VERSION ""

NS_ :

BS_:

BU_: BMS ZF ABS VCU

BO_ 2364576807 BMS_MSG02: 8 BMS
 SG_ DCL_Max_Current_Charge : 16|16@1+ (0.05,-1600) [-1600|1612.8] "A" Vector__XXX
 SG_ DCL_Max_Current_DisCharge : 0|16@1+ (0.05,-1600) [-1600|1612.8] "A" Vector__XXX

BO_ 2566832475 VDHR: 8 VCU
 SG_ HghRslutionTotalVehicleDistance : 0|32@1+ (0.005,0) [0|21055400] "km" Vector__XXX

BO_ 2364575953 BMS_MSG01: 8 BMS
 SG_ DCL_Current : 48|16@1+ (0.05,-16000) [-16000|16000] "A" Vector__XXX
 SG_ DCL_Volt : 32|16@1+ (0.05,0) [0|3212] "v" Vector__XXX

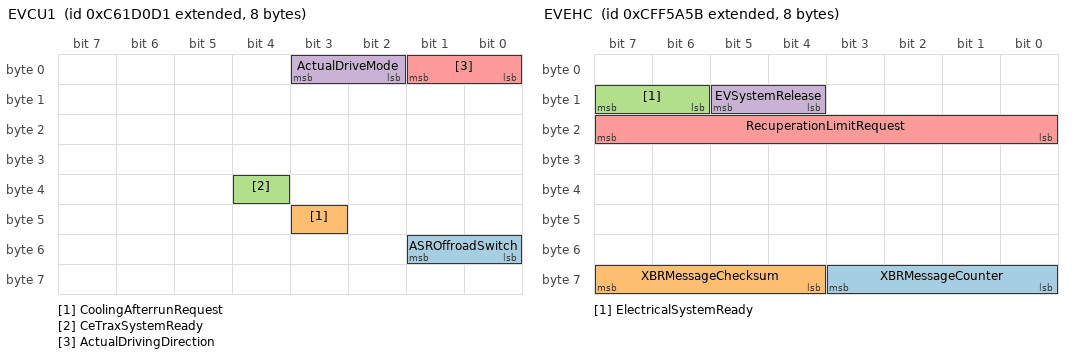
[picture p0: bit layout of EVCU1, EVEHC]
BO_ 2355220689 EVCU1: 8 Vector__XXX
 SG_ ASROffroadSwitch : 48|2@1+ (1,0) [0|3] "" Vector__XXX
 SG_ CoolingAfterrunRequest : 43|1@1+ (1,0) [0|1] "" Vector__XXX
 SG_ CeTraxSystemReady : 36|1@1+ (1,0) [0|0] "" Vector__XXX
 SG_ ActualDriveMode : 2|2@1+ (1,0) [0|0] "" Vector__XXX
 SG_ ActualDrivingDirection : 0|2@1+ (1,0) [0|0] "" Vector__XXX

BO_ 2348876635 TC1_Ext: 8 Vector__XXX
 SG_ Disengage_Driveline_Request : 0|2@1+ (1,0) [0|3] "" Vector__XXX

BO_ 2566871643 BMS_MSG06: 8 VCU
 SG_ DCL_Min_Voltage : 16|16@1+ (0.05,0) [0|3212.75] "" Vector__XXX
 SG_ DCL_Max_Voltage : 0|16@1+ (0.05,0) [0|3212.75] "" Vector__XXX

BO_ 2566698791 BMS_MSG03: 8 BMS
 SG_ State_Of_Charge : 0|16@1+ (0.0025,0) [0|160.6375] "%" Vector__XXX

BO_ 2365545051 EVEHC: 8 VCU
 SG_ XBRMessageCounter : 56|4@1+ (1,0) [0|15] "" Vector__XXX
 SG_ XBRMessageChecksum : 60|4@1+ (1,0) [0|15] "" Vector__XXX
 SG_ ElectricalSystemReady : 14|2@1+ (1,0) [0|3] "" Vector__XXX
 SG_ EVSystemRelease : 12|2@1+ (1,0) [0|3] "" Vector__XXX
 SG_ RecuperationLimitRequest : 16|8@1+ (0.4,0) [0|100] "%" Vector__XXX

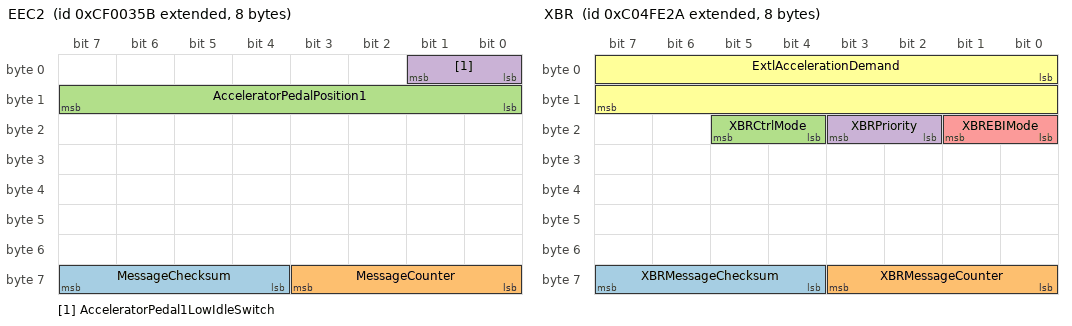
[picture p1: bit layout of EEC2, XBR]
BO_ 2364539739 EEC2: 8 VCU
 SG_ MessageChecksum : 60|4@1+ (1,0) [0|15] "" Vector__XXX
 SG_ MessageCounter : 56|4@1+ (1,0) [0|15] "" Vector__XXX
 SG_ AcceleratorPedalPosition1 : 8|8@1+ (0.4,0) [0|100] "%" Vector__XXX
 SG_ AcceleratorPedal1LowIdleSwitch : 0|2@1+ (1,0) [0|3] "" Vector__XXX

BO_ 2566845787 AMB: 8 VCU
 SG_ AMB1 : 16|16@1+ (0.03125,-273) [-273|1734] "deg C" Vector__XXX

BO_ 2349137450 XBR: 8 Vector__XXX
 SG_ XBRMessageChecksum : 60|4@1+ (1,0) [0|15] "" Vector__XXX
 SG_ XBRMessageCounter : 56|4@1+ (1,0) [0|15] "" Vector__XXX
 SG_ XBRCtrlMode : 20|2@1+ (1,0) [0|3] "" Vector__XXX
 SG_ XBRPriority : 18|2@1+ (1,0) [0|3] "" Vector__XXX
 SG_ XBREBIMode : 16|2@1+ (1,0) [0|3] "" Vector__XXX
 SG_ ExtlAccelerationDemand : 0|16@1+ (0.000488281,-15.687) [-15.687|15.687] "m/s²" Vector__XXX

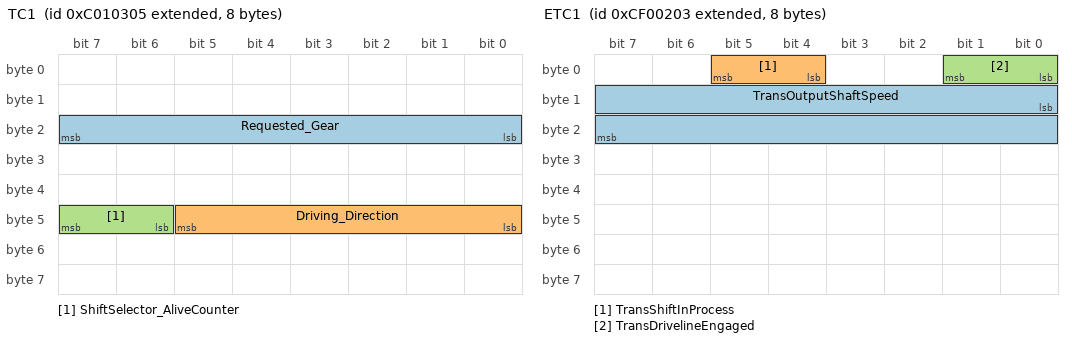
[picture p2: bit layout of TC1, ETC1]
BO_ 2348876549 TC1: 8 Vector__XXX
 SG_ Requested_Gear : 16|8@1+ (1,0) [125|252] "" Vector__XXX
 SG_ Driving_Direction : 40|6@1+ (1,0) [0|0] "" Vector__XXX
 SG_ ShiftSelector_AliveCounter : 46|2@1+ (1,0) [0|3] "" Vector__XXX

BO_ 2566840580 RC: 19 Vector__XXX
 SG_ PercentTorqueAtPeakTorquePoint5 : 144|8@1+ (1,-125) [-125|125] "%" Vector__XXX
 SG_ ReferenceRetarderTorque : 128|16@1+ (1,0) [0|64255] "Nm" Vector__XXX
 SG_ RetarderSpeedAtPeakTorquePoint5 : 112|16@1+ (0.125,0) [0|8031.88] "rpm" Vector__XXX
 SG_ PercentTorqueAtPoint4 : 104|8@1+ (1,-125) [-125|125] "%" Vector__XXX
 SG_ RetarderSpeedAtPoint4 : 88|16@1+ (0.125,0) [0|8031.88] "rpm" Vector__XXX
 SG_ PercentTorqueAtPoint3 : 80|8@1+ (1,-125) [-125|125] "%" Vector__XXX
 SG_ RetarderSpeedAtPoint3 : 64|16@1+ (0.125,0) [0|8031.88] "rpm" Vector__XXX
 SG_ PercentTorqueAtMaxSpeedPoint2 : 56|8@1+ (1,-125) [-125|125] "%" Vector__XXX
 SG_ MaxRetarderSpeedPoint2 : 40|16@1+ (0.125,0) [0|8031.88] "rpm" Vector__XXX
 SG_ PercentTorqueAtIdlePoint1 : 32|8@1+ (1,-125) [-125|125] "%" Vector__XXX
 SG_ RetarderSpeedAtIdlePoint1 : 16|16@1+ (0.125,0) [0|8031.88] "rpm" Vector__XXX
 SG_ DrivingDirection : 8|32@1+ (1,0) [0|250] "steps" Vector__XXX
 SG_ RetarderLocation : 4|4@1+ (1,0) [0|15] "" Vector__XXX
 SG_ RetarderType : 0|4@1+ (1,0) [0|15] "" Vector__XXX

BO_ 2566801923 ETC7: 8 Vector__XXX
 SG_ TransReadyForBrakeRelease : 8|2@1+ (1,0) [0|3] "" Vector__XXX

BO_ 2565866755 ETC2: 8 Vector__XXX
 SG_ TransCurrentGear : 24|8@1+ (1,-125) [-125|125] "" Vector__XXX
 SG_ TransSelectedGear : 0|8@1+ (1,-125) [-125|125] "" Vector__XXX

BO_ 2364539395 ETC1: 8 Vector__XXX
 SG_ TransOutputShaftSpeed : 8|16@1+ (0.125,0) [0|8031.88] "rpm" Vector__XXX
 SG_ TransShiftInProcess : 4|2@1+ (1,0) [0|3] "" Vector__XXX
 SG_ TransDrivelineEngaged : 0|2@1+ (1,0) [0|3] "" Vector__XXX

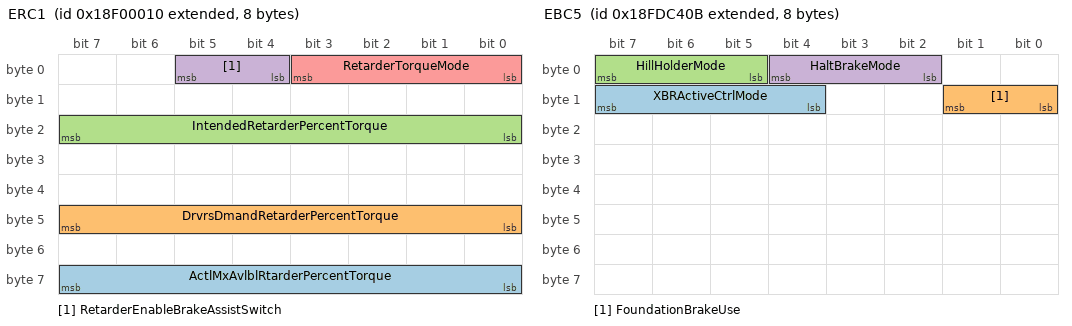
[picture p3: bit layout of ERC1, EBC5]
BO_ 2565865488 ERC1: 8 Vector__XXX
 SG_ ActlMxAvlblRtarderPercentTorque : 56|8@1+ (1,-125) [-125|125] "%" Vector__XXX
 SG_ DrvrsDmandRetarderPercentTorque : 40|8@1+ (1,-125) [-125|125] "%" Vector__XXX
 SG_ IntendedRetarderPercentTorque : 16|8@1+ (1,-125) [-125|125] "%" Vector__XXX
 SG_ RetarderEnableBrakeAssistSwitch : 4|2@1+ (1,0) [0|3] "" Vector__XXX
 SG_ RetarderTorqueMode : 0|4@1+ (1,0) [0|15] "" Vector__XXX

BO_ 2566841088 EC1: 21 Vector__XXX
 SG_ EngReferenceTorque : 152|16@1+ (1,0) [0|64255] "Nm" Vector__XXX
 SG_ EngPercentTorqueAtPoint5 : 112|8@1+ (1,-125) [-125|125] "%" Vector__XXX
 SG_ EngSpeedAtPoint5 : 96|16@1+ (0.125,0) [0|8031.88] "rpm" Vector__XXX
 SG_ EngPercentTorqueAtPoint4 : 88|8@1+ (1,-125) [-125|125] "%" Vector__XXX
 SG_ EngSpeedAtPoint4 : 72|16@1+ (0.125,0) [0|8031.88] "rpm" Vector__XXX
 SG_ EngPercentTorqueAtPoint3 : 64|8@1+ (1,-125) [-125|125] "%" Vector__XXX
 SG_ EngSpeedAtPoint3 : 48|16@1+ (0.125,0) [0|8031.88] "rpm" Vector__XXX
 SG_ EngPercentTorqueAtPoint2 : 40|8@1+ (1,-125) [-125|125] "%" Vector__XXX
 SG_ EngSpeedAtPoint2 : 24|16@1+ (0.125,0) [0|8031.88] "rpm" Vector__XXX
 SG_ EngPercentTorqueAtIdlePoint1 : 16|8@1+ (1,-125) [-125|125] "%" Vector__XXX
 SG_ EngSpeedAtIdlePoint1 : 0|16@1+ (0.125,0) [0|8031.88] "rpm" Vector__XXX

BO_ 2566767627 EBC5: 8 ABS
 SG_ XBRActiveCtrlMode : 12|4@1+ (1,0) [0|15] "" Vector__XXX
 SG_ FoundationBrakeUse : 8|2@1+ (1,0) [0|3] "" Vector__XXX
 SG_ HillHolderMode : 5|3@1+ (1,0) [0|7] "" Vector__XXX
 SG_ HaltBrakeMode : 2|3@1+ (1,0) [0|7] "" Vector__XXX

BO_ 2566831883 EBC2: 8 ABS
 SG_ FrontAxleSpeed : 0|16@1+ (0.00390625,0) [0|250.996] "km/h" Vector__XXX

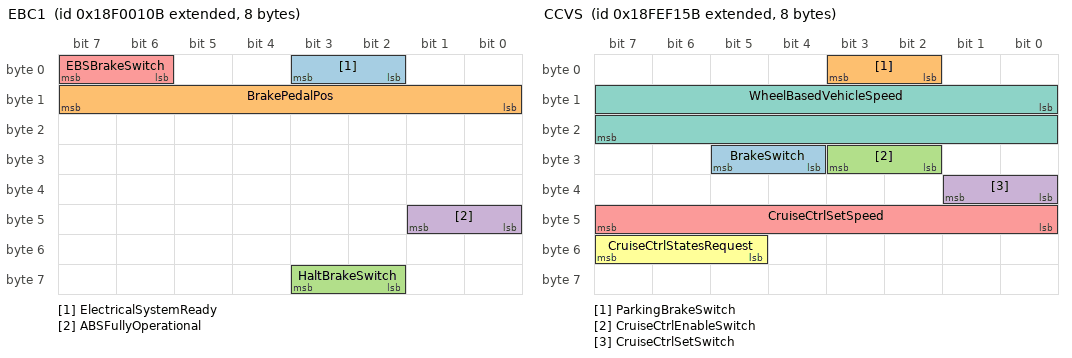
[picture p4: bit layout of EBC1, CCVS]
BO_ 2565865739 EBC1: 8 ABS
 SG_ ElectricalSystemReady : 2|2@1+ (1,0) [0|3] "" Vector__XXX
 SG_ BrakePedalPos : 8|8@1+ (0.4,0) [0|100] "%" Vector__XXX
 SG_ HaltBrakeSwitch : 58|2@1+ (1,0) [0|3] "" Vector__XXX
 SG_ ABSFullyOperational : 40|2@1+ (1,0) [0|3] "" Vector__XXX
 SG_ EBSBrakeSwitch : 6|2@1+ (1,0) [0|3] "" Vector__XXX

BO_ 2566844763 CCVS: 8 VCU
 SG_ BrakeSwitch : 28|2@1+ (1,0) [0|3] "" Vector__XXX
 SG_ ParkingBrakeSwitch : 2|2@1+ (1,0) [0|3] "" Vector__XXX
 SG_ CruiseCtrlEnableSwitch : 26|2@1+ (1,0) [0|3] "" Vector__XXX
 SG_ CruiseCtrlSetSwitch : 32|2@1+ (1,0) [0|3] "" Vector__XXX
 SG_ CruiseCtrlSetSpeed : 40|8@1+ (1,0) [0|250] "km/h" Vector__XXX
 SG_ CruiseCtrlStatesRequest : 53|3@1+ (1,0) [0|7] "sts" Vector__XXX
 SG_ WheelBasedVehicleSpeed : 8|16@1+ (0.00390625,0) [0|250] "km/h" Vector__XXX

BO_ 2566834778 DM1: 22 ZF
 SG_ FlashRedStopLamp : 12|2@1+ (1,0) [0|3] "" Vector__XXX
 SG_ FlashProtectLamp : 8|2@1+ (1,0) [0|3] "" Vector__XXX
 SG_ FlashMalfuncIndicatorLamp : 14|2@1+ (1,0) [0|3] "" Vector__XXX
 SG_ FlashAmberWarningLamp : 10|2@1+ (1,0) [0|3] "" Vector__XXX
 SG_ MalfunctionIndicatorLampStatus : 6|2@1+ (1,0) [0|3] "" Vector__XXX
 SG_ AmberWarningLampStatus : 2|2@1+ (1,0) [0|3] "" Vector__XXX
 SG_ RedStopLampState : 4|2@1+ (1,0) [0|3] "" Vector__XXX
 SG_ ProtectLampStatus : 0|2@1+ (1,0) [0|3] "" Vector__XXX
 SG_ DTC5 : 144|32@1+ (1,0) [-1|0] "" Vector__XXX
 SG_ DTC4 : 112|32@1+ (1,0) [-1|0] "" Vector__XXX
 SG_ DTC3 : 80|32@1+ (1,0) [-1|0] "" Vector__XXX
 SG_ DTC2 : 48|32@1+ (1,0) [-1|0] "" Vector__XXX
 SG_ DTC1 : 16|32@1+ (1,0) [-1|0] "" Vector__XXX

BO_ 2566846241 VEP: 8 Vector__XXX
 SG_ BATT_VOLTAGE_24V : 48|16@1+ (0.05,0) [0|3212.75] "V" Vector__XXX

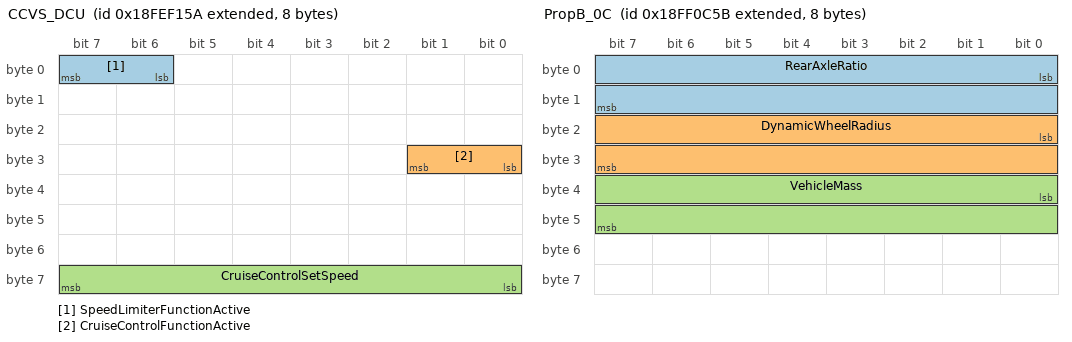
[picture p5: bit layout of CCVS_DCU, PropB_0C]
BO_ 2566844762 CCVS_DCU: 8 ZF
 SG_ SpeedLimiterFunctionActive : 6|2@1+ (1,0) [0|3] "" Vector__XXX
 SG_ CruiseControlFunctionActive : 24|2@1+ (1,0) [0|3] "" Vector__XXX
 SG_ CruiseControlSetSpeed : 56|8@1+ (1,0) [0|250] "kph" Vector__XXX

BO_ 2566851675 PropB_0C: 8 VCU
 SG_ RearAxleRatio : 0|16@1+ (0.01,0) [0|642.55] "" Vector__XXX
 SG_ DynamicWheelRadius : 16|16@1+ (0.1,0) [0|6425.5] "mm" Vector__XXX
 SG_ VehicleMass : 32|16@1+ (2,0) [0|128510] "kg" Vector__XXX

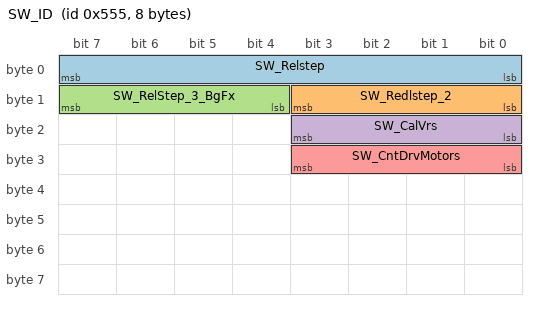
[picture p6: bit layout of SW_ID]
BO_ 1365 SW_ID: 8 ZF
 SG_ SW_Relstep : 0|8@1+ (1,0) [0|255] "b" Vector__XXX
 SG_ SW_Redlstep_2 : 8|4@1+ (1,0) [0|15] "" Vector__XXX
 SG_ SW_RelStep_3_BgFx : 12|4@1+ (1,0) [0|15] "" Vector__XXX
 SG_ SW_CalVrs : 16|4@1+ (1,0) [0|255] "" Vector__XXX
 SG_ SW_CntDrvMotors : 24|4@1+ (1,0) [0|15] "" Vector__XXX

CM_ BO_ 2364576807 "HVESSD5";
CM_ BO_ 2566832475 "High Resolution Vehicle Distance";
CM_ SG_ 2566832475 HghRslutionTotalVehicleDistance "Accumulated distance traveled by the vehicle during its operation.";
CM_ BO_ 2364575953 "HVESSD1 ";
CM_ SG_ 2355220689 ASROffroadSwitch "Switch signal which indicates the position of the ASR off-road switch.";
CM_ SG_ 2355220689 CeTraxSystemReady "Ready status of system
";
CM_ SG_ 2355220689 ActualDriveMode "Working mode of CeTrax-System";
CM_ SG_ 2355220689 ActualDrivingDirection "Driving direction of the Vehicle (for using in a display, ..)";
CM_ BO_ 2348876635 "Command signal used to simply disengage the driveline, e.g., to prevent engine drag torque from causing high wheel slip
on slippery surfaces.";
CM_ SG_ 2348876635 Disengage_Driveline_Request "Command signal used to disengage the various differential locks, e.";
CM_ BO_ 2566871643 "propB";
CM_ SG_ 2566871643 DCL_Min_Voltage "constant value to be sent 576V";
CM_ SG_ 2566871643 DCL_Max_Voltage "constat value to be sent 786volt";
CM_ BO_ 2566698791 " HSS2 ";
CM_ SG_ 2566698791 State_Of_Charge "ESS State of Charge (SOC)
State_Of_Charge

";
CM_ SG_ 2365545051 XBRMessageCounter "The XBR message counter is to verify the signal path from the demanding device to the brake controller on electronic";
CM_ SG_ 2365545051 XBRMessageChecksum "The XBR message checksum is used to verify the signal path from the demanding device to the brake controller on";
CM_ SG_ 2365545051 ElectricalSystemReady "State signal which indicates that ASR brake control is active.";
CM_ SG_ 2365545051 EVSystemRelease "Additional Release Request by the Driver  or Vehicle Controller (comparable to Kl50) to release the Driveline";
CM_ SG_ 2365545051 RecuperationLimitRequest "Signal which can include different type of retarder lever values  (e.g. relative value from 0-100%, sts-values or enable bit value) for limitation or request of recuperation;
The signal is mandatory for driving \"One Pedal\"-Driving Strategy ";
CM_ SG_ 2364539739 MessageChecksum "The checksum is used to verify the signal path from the transmitting device to the receiving device.";
CM_ SG_ 2364539739 MessageCounter "The message counter is used to detect situations where the transmitting ECU malfunction repeats the same frame all the time.";
CM_ SG_ 2364539739 AcceleratorPedalPosition1 "FE - error
FF - not available";
CM_ SG_ 2364539739 AcceleratorPedal1LowIdleSwitch "1 = low idle sw active
0 = low idle sw inactive";
CM_ BO_ 2566845787 "ambient temperature";
CM_ SG_ 2566845787 AMB1 "Ambient Air Temperture";
CM_ BO_ 2349137450 "External Brake Request";
CM_ SG_ 2349137450 XBRMessageChecksum "The XBR message checksum is used to verify the signal path from the demanding device to the brake controller on";
CM_ SG_ 2349137450 XBRMessageCounter "The XBR message counter is to verify the signal path from the demanding device to the brake controller on electronic";
CM_ SG_ 2349137450 XBRCtrlMode "The XBR Control Mode is used as an input to the brake system and defines how the external acceleration demand has to";
CM_ SG_ 2349137450 XBRPriority "The XBR Priority is used as an input to the brake system to manage the priority of overlapping external and internal requests.";
CM_ SG_ 2349137450 XBREBIMode "The XBR EBI (Endurance Brake Integration) Mode is used as an input for the brake system to prescribe the use of";
CM_ SG_ 2349137450 ExtlAccelerationDemand "Parameter provided to the brake system from external sources.";
CM_ BO_ 2348876549 "Transmission Control 1";
CM_ SG_ 2348876549 Requested_Gear "
";
CM_ BO_ 2566840580 "Retarder Configuration";
CM_ SG_ 2566840580 PercentTorqueAtPeakTorquePoint5 "The torque limit that indicates the available retarder torque which can be provided by the retarder at point 5 of the retarder";
CM_ SG_ 2566840580 ReferenceRetarderTorque "This parameter is the 100% reference value for all defined indicated retarder torque parameters.";
CM_ SG_ 2566840580 RetarderSpeedAtPeakTorquePoint5 "Please reference PGN 65249";
CM_ SG_ 2566840580 PercentTorqueAtPoint4 "The torque limit that indicates the available retarder torque which can be provided by the retarder at points 3 and 4 of the";
CM_ SG_ 2566840580 RetarderSpeedAtPoint4 "Retarder speed of point 4 of the engine retarder torque map.";
CM_ SG_ 2566840580 PercentTorqueAtPoint3 "The torque limit that indicates the available retarder torque which can be provided by the retarder at points 3 and 4 of the";
CM_ SG_ 2566840580 RetarderSpeedAtPoint3 "Retarder speed of point 3 of the engine retarder torque map.";
CM_ SG_ 2566840580 PercentTorqueAtMaxSpeedPoint2 "The torque limit that indicates the available retarder torque which can be provided by the retarder at its maximum speed.";
CM_ SG_ 2566840580 MaxRetarderSpeedPoint2 "Maximum speed of retarder (Please reference PGN 65249).";
CM_ SG_ 2566840580 PercentTorqueAtIdlePoint1 "The torque limit that indicates the available retarder torque which can be provided by the retarder at idle speed.";
CM_ SG_ 2566840580 RetarderSpeedAtIdlePoint1 "Please reference PGN 65249";
CM_ SG_ 2566840580 DrivingDirection "Bits direction coding of the bit couples
0,1 neutral N
2,3 forward D..D3 
4,5 reverse 00: direction not active
01:direction is active
10 error
11 undefined

notice
 If no button is pressed, 
all three direction bit couples are set to 00
";
CM_ SG_ 2566840580 RetarderLocation "This parameter defines whether the “torque/speed curve” defined by the retarder configuration message (PGN 65249) is";
CM_ SG_ 2566840580 RetarderType "A vehicle retarder is a supplementary device to the wheel brakes for the driver to better control the vehicle.";
CM_ BO_ 2566801923 "Electronic Transmission Controller 7";
CM_ SG_ 2566801923 TransReadyForBrakeRelease "This parameter indicates that enough torque / motive force is available at the transmission output shaft to release all the";
CM_ BO_ 2565866755 "Electronic Transmission Controller 2";
CM_ SG_ 2565866755 TransCurrentGear "The gear currently engaged in the transmission or the last gear engaged while the transmission is in the process of";
CM_ SG_ 2565866755 TransSelectedGear "The gear that the transmission will attempt to achieve during the current shift if a shift is in progress, or the next shift if one";
CM_ BO_ 2364539395 "Electronic Transmission Controller 1";
CM_ SG_ 2364539395 TransOutputShaftSpeed "Calculated speed of the transmission output shaft.";
CM_ SG_ 2364539395 TransShiftInProcess "Indicates that the transmission is in process of shifting from the current gear to the selected gear.";
CM_ SG_ 2364539395 TransDrivelineEngaged "Driveline engaged indicates the transmission controlled portion of the driveline is engaged sufficiently to allow a transfer";
CM_ BO_ 2565865488 "Electronic Retarder Controller 1";
CM_ SG_ 2565865488 ActlMxAvlblRtarderPercentTorque "This is the maximum amount of torque that the retarder can immediately deliver.";
CM_ SG_ 2565865488 DrvrsDmandRetarderPercentTorque "The Drivers demand retarder – percent torque is the maximum torque selected by the driver when one or more modes";
CM_ SG_ 2565865488 IntendedRetarderPercentTorque "Braking torque of retarder that the retarder is currently trying to achieve.";
CM_ SG_ 2565865488 RetarderEnableBrakeAssistSwitch "Switch signal which indicates whether the operator wishes the retarder to be enabled for vehicle braking assist.";
CM_ SG_ 2565865488 RetarderTorqueMode "State signal which indicates which retarder torque mode is currently generating, limiting, or controlling the torque.";
CM_ BO_ 2566841088 "Engine Configuration 1";
CM_ SG_ 2566841088 EngReferenceTorque "This parameter is the 100% reference value for all defined indicated engine torque parameters.";
CM_ SG_ 2566841088 EngPercentTorqueAtPoint5 "The torque limit that indicates the available engine torque which can be provided by the engine at point 3, 4, and 5 of the";
CM_ SG_ 2566841088 EngSpeedAtPoint5 "Engine speed of point 3, 4, and 5 of the engine torque map (see PGN 65251 and supporting document).";
CM_ SG_ 2566841088 EngPercentTorqueAtPoint4 "The torque limit that indicates the available engine torque which can be provided by the engine at point 3, 4, and 5 of the";
CM_ SG_ 2566841088 EngSpeedAtPoint4 "Engine speed of point 3, 4, and 5 of the engine torque map (see PGN 65251 and supporting document).";
CM_ SG_ 2566841088 EngPercentTorqueAtPoint3 "The torque limit that indicates the available engine torque which can be provided by the engine at point 3, 4, and 5 of the";
CM_ SG_ 2566841088 EngSpeedAtPoint3 "Engine speed of point 3, 4, and 5 of the engine torque map (see PGN 65251 and supporting document).";
CM_ SG_ 2566841088 EngPercentTorqueAtPoint2 "The torque limit that indicates the available engine torque which can be provided by the engine at point 2 of the engine";
CM_ SG_ 2566841088 EngSpeedAtPoint2 "Engine speed of point 2 of the engine torque map (see PGN 65251 and supporting document).";
CM_ SG_ 2566841088 EngPercentTorqueAtIdlePoint1 "The torque limit that indicates the available engine torque which can be provided by the engine at idle speed.";
CM_ SG_ 2566841088 EngSpeedAtIdlePoint1 "Stationary low idle speed of engine which includes influences due to engine temperature (after power up) and other";
CM_ BO_ 2566767627 "Electronic Brake Controller 5";
CM_ SG_ 2566767627 XBRActiveCtrlMode "This parameter indicates which XBR Control Mode is executed by the brake system.";
CM_ SG_ 2566767627 FoundationBrakeUse "This parameter indicates if the brake system presently uses the foundation brakes.";
CM_ SG_ 2566767627 HillHolderMode "Signal which indicates the current mode of the hill holder function.";
CM_ SG_ 2566767627 HaltBrakeMode "Signal which indicates the current mode of the halt brake function.";
CM_ BO_ 2566831883 "Wheel Speed Information";
CM_ SG_ 2566831883 FrontAxleSpeed "The average speed of the two front wheels.";
CM_ BO_ 2565865739 "Electronic Brake Controller 1";
CM_ SG_ 2565865739 ElectricalSystemReady "State signal which indicates that ASR brake control is active.";
CM_ SG_ 2565865739 BrakePedalPos "Ratio of brake pedal position to maximum pedal position.";
CM_ SG_ 2565865739 HaltBrakeSwitch "Switch signal which indicates the position of the halt brake switch.";
CM_ SG_ 2565865739 ABSFullyOperational "Signal which indicates whether an ABS system is fully operational or whether its functionality is reduced by a defect or by";
CM_ SG_ 2565865739 EBSBrakeSwitch "Switch signal which indicates that the brake pedal is being pressed.";
CM_ BO_ 2566844763 "Cruise Control/Vehicle Speed";
CM_ SG_ 2566844763 BrakeSwitch "Switch signal which indicates that the driver operated brake foot pedal is being pressed.";
CM_ SG_ 2566844763 ParkingBrakeSwitch "Switch signal which indicates when the parking brake is set.";
CM_ SG_ 2566844763 CruiseCtrlEnableSwitch "Set Switch indication 
(Activate EVCU specific function, e.g. Speed Limitation, depending on the current send Cruise Control State Request)";
CM_ SG_ 2566844763 CruiseCtrlSetSwitch "Set Switch indication 
(Activate EVCU specific function, e.g. Speed Limitation, depending on the current send Cruise Control State Request)";
CM_ SG_ 2566844763 CruiseCtrlSetSpeed "Cruise Control Set Speed
(Speed Signal to EVCU for Limiting or keep the Speed)";
CM_ SG_ 2566844763 CruiseCtrlStatesRequest "1 - Cruise Control Request 
6- Speed Limiter Request

";
CM_ SG_ 2566844763 WheelBasedVehicleSpeed "Wheelbased Vehicle Speed";
CM_ BO_ 2566834778 "Active diagnostic trouble codes";
CM_ SG_ 2566834778 FlashRedStopLamp "This parameter provides the capability to flash the RSL (SPN 3039).";
CM_ SG_ 2566834778 FlashProtectLamp "This parameter provides the capability to flash the engine protect lamp (SPN 3041).";
CM_ SG_ 2566834778 FlashMalfuncIndicatorLamp "This parameter provides the capability to flash the MIL (SPN 3038).";
CM_ SG_ 2566834778 FlashAmberWarningLamp "This parameter provides the capability to flash the AWL (SPN 3040). ";
CM_ SG_ 2566834778 MalfunctionIndicatorLampStatus "A lamp used to relay only emissions-related trouble code information.";
CM_ SG_ 2566834778 AmberWarningLampStatus "This lamp is used to relay trouble code information that is reporting a problem with the vehicle system but the vehicle need
not be immediately stopped.";
CM_ SG_ 2566834778 RedStopLampState "This lamp is uesed to relay trouble code information that is of a severe enought condition that it warrants stopping the vehicle.";
CM_ SG_ 2566834778 ProtectLampStatus "This lamp is used to relay trouble code informatio that is reporting a problem with a vehicle system that is most
probably not electronic subsystem related.";
CM_ SG_ 2566834778 DTC5 "Diagnostic Trouble Code";
CM_ SG_ 2566834778 DTC4 "Diagnostic Trouble Code";
CM_ SG_ 2566834778 DTC3 "Diagnostic Trouble Code";
CM_ SG_ 2566834778 DTC2 "Diagnostic Trouble Code";
CM_ SG_ 2566834778 DTC1 "Diagnostic Trouble Code";
CM_ BO_ 2566846241 "Vehicle Electrical Power 1";
CM_ SG_ 2566846241 BATT_VOLTAGE_24V "Battery potential measured at the input of the electronic control unit supplied through a keyswitch or similar switching";
CM_ BO_ 2566844762 "CCVS feedback message from DCU";
CM_ SG_ 2566844762 SpeedLimiterFunctionActive "Indication that speed limiter is active";
CM_ SG_ 2566844762 CruiseControlFunctionActive "Indication that cruise control is active";
CM_ SG_ 2566844762 CruiseControlSetSpeed "Speed limiter set speed in kph
";
CM_ BO_ 2566851675 "Cetrax config message
";
CM_ SG_ 2566851675 VehicleMass "Total mass imposed on the road surface by all the tires in the axle group";
CM_ BO_ 1365 "ZF SW ID";
CM_ SG_ 1365 SW_Relstep "Software Release Step";
CM_ SG_ 1365 SW_Redlstep_2 "Software Release Step 2";
CM_ SG_ 1365 SW_RelStep_3_BgFx "Software Release Step Bug Fix Version";
CM_ SG_ 1365 SW_CalVrs "Software Calibration Version";
CM_ SG_ 1365 SW_CntDrvMotors "Number of Drive Motors";
BA_DEF_ SG_  "SigType" ENUM  "Default","Range","RangeSigned","ASCII","Discrete","Control","ReferencePGN","DTC","StringDelimiter","StringLength","StringLengthControl";
BA_DEF_ SG_  "GenSigStartValue" INT 0 10000;
BA_DEF_ SG_  "GenSigSendType" ENUM  "Cyclic","OnWrite","reserved","OnChange","reserved","reserved","reserved","NoSigSendType";
BA_DEF_ SG_  "GenSigILSupport" ENUM  "Yes","No";
BA_DEF_ SG_  "GenSigEVName" STRING ;
BA_DEF_ SG_  "SPN" INT 0 524287;
BA_DEF_ BO_  "GenMsgStartDelayTime" INT 0 100000;
BA_DEF_ BO_  "GenMsgILSupport" ENUM  "Yes","No";
BA_DEF_ BO_  "GenMsgRequestable" INT 0 1;
BA_DEF_ BO_  "GenMsgSendType" ENUM  "cyclic","reserved","cyclicIfActive","reserved","reserved","reserved","reserved","reserved","noMsgSendType";
BA_DEF_ BO_  "VFrameFormat" ENUM  "StandardCAN","ExtendedCAN","reserved","J1939PG";
BA_DEF_ BO_  "GenMsgCycleTime" INT 0 3600000;
BA_DEF_ BU_  "NmStationAddress" INT 0 255;
BA_DEF_ BU_  "NmJ1939Function" INT 0 255;
BA_DEF_  "DatabaseVersion" STRING ;
BA_DEF_  "BusType" STRING ;
BA_DEF_  "ProtocolType" STRING ;
BA_DEF_  "SAE_J1939_75_SpecVersion" STRING ;
BA_DEF_  "SAE_J1939_21_SpecVersion" STRING ;
BA_DEF_  "SAE_J1939_73_SpecVersion" STRING ;
BA_DEF_  "SAE_J1939_71_SpecVersion" STRING ;
BA_DEF_DEF_  "SigType" "Default";
BA_DEF_DEF_  "GenSigStartValue" 0;
BA_DEF_DEF_  "GenSigSendType" "NoSigSendType";
BA_DEF_DEF_  "GenSigILSupport" "Yes";
BA_DEF_DEF_  "GenSigEVName" "Env@Nodename_@Signame";
BA_DEF_DEF_  "SPN" 0;
BA_DEF_DEF_  "GenMsgStartDelayTime" 0;
BA_DEF_DEF_  "GenMsgILSupport" "Yes";
BA_DEF_DEF_  "GenMsgRequestable" 1;
BA_DEF_DEF_  "GenMsgSendType" "noMsgSendType";
BA_DEF_DEF_  "VFrameFormat" "J1939PG";
BA_DEF_DEF_  "GenMsgCycleTime" 0;
BA_DEF_DEF_  "NmStationAddress" 254;
BA_DEF_DEF_  "NmJ1939Function" 0;
BA_DEF_DEF_  "DatabaseVersion" "";
BA_DEF_DEF_  "BusType" "";
BA_DEF_DEF_  "ProtocolType" "";
BA_DEF_DEF_  "SAE_J1939_75_SpecVersion" "";
BA_DEF_DEF_  "SAE_J1939_21_SpecVersion" "";
BA_DEF_DEF_  "SAE_J1939_73_SpecVersion" "";
BA_DEF_DEF_  "SAE_J1939_71_SpecVersion" "";
BA_ "SAE_J1939_71_SpecVersion" "2009-09";
BA_ "SAE_J1939_73_SpecVersion" "2009-09";
BA_ "SAE_J1939_21_SpecVersion" "2006-10";
BA_ "SAE_J1939_75_SpecVersion" "2005-10";
BA_ "ProtocolType" "J1939";
BA_ "BusType" "CAN";
BA_ "DatabaseVersion" "7.2";
BA_ "GenMsgCycleTime" BO_ 2364576807 100;
BA_ "SPN" SG_ 2364576807 DCL_Max_Current_Charge 1794;
BA_ "SigType" SG_ 2364576807 DCL_Max_Current_Charge 1;
BA_ "GenMsgSendType" BO_ 2566832475 0;
BA_ "GenMsgCycleTime" BO_ 2566832475 1000;
BA_ "SPN" SG_ 2566832475 HghRslutionTotalVehicleDistance 917;
BA_ "SigType" SG_ 2566832475 HghRslutionTotalVehicleDistance 1;
BA_ "GenMsgCycleTime" BO_ 2364575953 100;
BA_ "SPN" SG_ 2364575953 DCL_Current 8083;
BA_ "SigType" SG_ 2364575953 DCL_Current 1;
BA_ "GenMsgCycleTime" BO_ 2355220689 10;
BA_ "SPN" SG_ 2355220689 ASROffroadSwitch 576;
BA_ "SigType" SG_ 2355220689 ASROffroadSwitch 4;
BA_ "SPN" SG_ 2355220689 CoolingAfterrunRequest 3154;
BA_ "SPN" SG_ 2348876635 Disengage_Driveline_Request 689;
BA_ "SigType" SG_ 2348876635 Disengage_Driveline_Request 4;
BA_ "GenMsgStartDelayTime" BO_ 2566871643 100;
BA_ "SPN" SG_ 2566871643 DCL_Min_Voltage 8116;
BA_ "GenMsgCycleTime" BO_ 2566698791 1000;
BA_ "SPN" SG_ 2566698791 State_Of_Charge 3146;
BA_ "GenMsgCycleTime" BO_ 2365545051 50;
BA_ "SPN" SG_ 2365545051 XBRMessageCounter 3189;
BA_ "SigType" SG_ 2365545051 XBRMessageCounter 4;
BA_ "SPN" SG_ 2365545051 XBRMessageChecksum 3188;
BA_ "SigType" SG_ 2365545051 XBRMessageChecksum 4;
BA_ "SPN" SG_ 2365545051 ElectricalSystemReady 562;
BA_ "SigType" SG_ 2365545051 ElectricalSystemReady 4;
BA_ "SPN" SG_ 2364539739 MessageChecksum 4207;
BA_ "SPN" SG_ 2364539739 MessageCounter 4206;
BA_ "SPN" SG_ 2364539739 AcceleratorPedalPosition1 91;
BA_ "SigType" SG_ 2364539739 AcceleratorPedalPosition1 1;
BA_ "GenMsgCycleTime" BO_ 2566845787 1000;
BA_ "SPN" SG_ 2566845787 AMB1 171;
BA_ "SigType" SG_ 2566845787 AMB1 1;
BA_ "GenMsgCycleTime" BO_ 2349137450 20;
BA_ "GenMsgSendType" BO_ 2349137450 2;
BA_ "SPN" SG_ 2349137450 XBRMessageChecksum 3188;
BA_ "SigType" SG_ 2349137450 XBRMessageChecksum 4;
BA_ "SPN" SG_ 2349137450 XBRMessageCounter 3189;
BA_ "SigType" SG_ 2349137450 XBRMessageCounter 4;
BA_ "SPN" SG_ 2349137450 XBRCtrlMode 2916;
BA_ "SigType" SG_ 2349137450 XBRCtrlMode 4;
BA_ "SPN" SG_ 2349137450 XBRPriority 2915;
BA_ "SigType" SG_ 2349137450 XBRPriority 4;
BA_ "SPN" SG_ 2349137450 XBREBIMode 2914;
BA_ "SigType" SG_ 2349137450 XBREBIMode 4;
BA_ "SPN" SG_ 2349137450 ExtlAccelerationDemand 2920;
BA_ "SigType" SG_ 2349137450 ExtlAccelerationDemand 1;
BA_ "SPN" SG_ 2348876549 Requested_Gear 683;
BA_ "SigType" SG_ 2348876549 Requested_Gear 4;
BA_ "SPN" SG_ 2348876549 Driving_Direction 682;
BA_ "SigType" SG_ 2348876549 Driving_Direction 4;
BA_ "SigType" SG_ 2348876549 ShiftSelector_AliveCounter 4;
BA_ "SPN" SG_ 2566840580 PercentTorqueAtPeakTorquePoint5 555;
BA_ "SigType" SG_ 2566840580 PercentTorqueAtPeakTorquePoint5 1;
BA_ "SPN" SG_ 2566840580 ReferenceRetarderTorque 556;
BA_ "SigType" SG_ 2566840580 ReferenceRetarderTorque 1;
BA_ "SPN" SG_ 2566840580 RetarderSpeedAtPeakTorquePoint5 547;
BA_ "SigType" SG_ 2566840580 RetarderSpeedAtPeakTorquePoint5 1;
BA_ "SPN" SG_ 2566840580 PercentTorqueAtPoint4 554;
BA_ "SigType" SG_ 2566840580 PercentTorqueAtPoint4 1;
BA_ "SPN" SG_ 2566840580 RetarderSpeedAtPoint4 550;
BA_ "SigType" SG_ 2566840580 RetarderSpeedAtPoint4 1;
BA_ "SPN" SG_ 2566840580 PercentTorqueAtPoint3 553;
BA_ "SigType" SG_ 2566840580 PercentTorqueAtPoint3 1;
BA_ "SPN" SG_ 2566840580 RetarderSpeedAtPoint3 549;
BA_ "SigType" SG_ 2566840580 RetarderSpeedAtPoint3 1;
BA_ "SPN" SG_ 2566840580 PercentTorqueAtMaxSpeedPoint2 552;
BA_ "SigType" SG_ 2566840580 PercentTorqueAtMaxSpeedPoint2 1;
BA_ "SPN" SG_ 2566840580 MaxRetarderSpeedPoint2 548;
BA_ "SigType" SG_ 2566840580 MaxRetarderSpeedPoint2 1;
BA_ "SPN" SG_ 2566840580 PercentTorqueAtIdlePoint1 551;
BA_ "SigType" SG_ 2566840580 PercentTorqueAtIdlePoint1 1;
BA_ "SPN" SG_ 2566840580 RetarderSpeedAtIdlePoint1 546;
BA_ "SigType" SG_ 2566840580 RetarderSpeedAtIdlePoint1 1;
BA_ "SigType" SG_ 2566840580 DrivingDirection 1;
BA_ "SPN" SG_ 2566840580 RetarderLocation 902;
BA_ "SigType" SG_ 2566840580 RetarderLocation 4;
BA_ "SPN" SG_ 2566840580 RetarderType 901;
BA_ "SigType" SG_ 2566840580 RetarderType 4;
BA_ "GenMsgCycleTime" BO_ 2566801923 100;
BA_ "GenMsgSendType" BO_ 2566801923 0;
BA_ "SPN" SG_ 2566801923 TransReadyForBrakeRelease 3086;
BA_ "SigType" SG_ 2566801923 TransReadyForBrakeRelease 4;
BA_ "GenMsgCycleTime" BO_ 2565866755 100;
BA_ "GenMsgSendType" BO_ 2565866755 0;
BA_ "SPN" SG_ 2565866755 TransCurrentGear 523;
BA_ "SigType" SG_ 2565866755 TransCurrentGear 1;
BA_ "SPN" SG_ 2565866755 TransSelectedGear 524;
BA_ "SigType" SG_ 2565866755 TransSelectedGear 1;
BA_ "GenMsgCycleTime" BO_ 2364539395 10;
BA_ "GenMsgSendType" BO_ 2364539395 0;
BA_ "SPN" SG_ 2364539395 TransOutputShaftSpeed 191;
BA_ "SigType" SG_ 2364539395 TransOutputShaftSpeed 1;
BA_ "SPN" SG_ 2364539395 TransShiftInProcess 574;
BA_ "SigType" SG_ 2364539395 TransShiftInProcess 4;
BA_ "SPN" SG_ 2364539395 TransDrivelineEngaged 560;
BA_ "SigType" SG_ 2364539395 TransDrivelineEngaged 4;
BA_ "GenMsgCycleTime" BO_ 2565865488 100;
BA_ "GenMsgSendType" BO_ 2565865488 0;
BA_ "SPN" SG_ 2565865488 ActlMxAvlblRtarderPercentTorque 1717;
BA_ "SigType" SG_ 2565865488 ActlMxAvlblRtarderPercentTorque 1;
BA_ "SPN" SG_ 2565865488 DrvrsDmandRetarderPercentTorque 1715;
BA_ "SigType" SG_ 2565865488 DrvrsDmandRetarderPercentTorque 1;
BA_ "SPN" SG_ 2565865488 IntendedRetarderPercentTorque 1085;
BA_ "SigType" SG_ 2565865488 IntendedRetarderPercentTorque 1;
BA_ "SPN" SG_ 2565865488 RetarderEnableBrakeAssistSwitch 571;
BA_ "SigType" SG_ 2565865488 RetarderEnableBrakeAssistSwitch 4;
BA_ "SPN" SG_ 2565865488 RetarderTorqueMode 900;
BA_ "SigType" SG_ 2565865488 RetarderTorqueMode 4;
BA_ "SPN" SG_ 2566841088 EngReferenceTorque 544;
BA_ "SigType" SG_ 2566841088 EngReferenceTorque 1;
BA_ "SPN" SG_ 2566841088 EngPercentTorqueAtPoint5 543;
BA_ "SigType" SG_ 2566841088 EngPercentTorqueAtPoint5 1;
BA_ "SPN" SG_ 2566841088 EngSpeedAtPoint5 531;
BA_ "SigType" SG_ 2566841088 EngSpeedAtPoint5 1;
BA_ "SPN" SG_ 2566841088 EngPercentTorqueAtPoint4 542;
BA_ "SigType" SG_ 2566841088 EngPercentTorqueAtPoint4 1;
BA_ "SPN" SG_ 2566841088 EngSpeedAtPoint4 530;
BA_ "SigType" SG_ 2566841088 EngSpeedAtPoint4 1;
BA_ "SPN" SG_ 2566841088 EngPercentTorqueAtPoint3 541;
BA_ "SigType" SG_ 2566841088 EngPercentTorqueAtPoint3 1;
BA_ "SPN" SG_ 2566841088 EngSpeedAtPoint3 529;
BA_ "SigType" SG_ 2566841088 EngSpeedAtPoint3 1;
BA_ "SPN" SG_ 2566841088 EngPercentTorqueAtPoint2 540;
BA_ "SigType" SG_ 2566841088 EngPercentTorqueAtPoint2 1;
BA_ "SPN" SG_ 2566841088 EngSpeedAtPoint2 528;
BA_ "SigType" SG_ 2566841088 EngSpeedAtPoint2 1;
BA_ "SPN" SG_ 2566841088 EngPercentTorqueAtIdlePoint1 539;
BA_ "SigType" SG_ 2566841088 EngPercentTorqueAtIdlePoint1 1;
BA_ "SPN" SG_ 2566841088 EngSpeedAtIdlePoint1 188;
BA_ "SigType" SG_ 2566841088 EngSpeedAtIdlePoint1 1;
BA_ "GenMsgCycleTime" BO_ 2566767627 100;
BA_ "GenMsgSendType" BO_ 2566767627 0;
BA_ "SPN" SG_ 2566767627 XBRActiveCtrlMode 2918;
BA_ "SigType" SG_ 2566767627 XBRActiveCtrlMode 4;
BA_ "SPN" SG_ 2566767627 FoundationBrakeUse 2919;
BA_ "SigType" SG_ 2566767627 FoundationBrakeUse 4;
BA_ "SPN" SG_ 2566767627 HillHolderMode 2912;
BA_ "SPN" SG_ 2566767627 HaltBrakeMode 2913;
BA_ "GenMsgCycleTime" BO_ 2566831883 100;
BA_ "GenMsgSendType" BO_ 2566831883 0;
BA_ "SPN" SG_ 2566831883 FrontAxleSpeed 904;
BA_ "SigType" SG_ 2566831883 FrontAxleSpeed 1;
BA_ "GenMsgCycleTime" BO_ 2565865739 100;
BA_ "GenMsgSendType" BO_ 2565865739 0;
BA_ "SPN" SG_ 2565865739 ElectricalSystemReady 562;
BA_ "SigType" SG_ 2565865739 ElectricalSystemReady 4;
BA_ "SPN" SG_ 2565865739 BrakePedalPos 1121;
BA_ "SigType" SG_ 2565865739 BrakePedalPos 1;
BA_ "SPN" SG_ 2565865739 HaltBrakeSwitch 2911;
BA_ "SigType" SG_ 2565865739 HaltBrakeSwitch 4;
BA_ "SPN" SG_ 2565865739 ABSFullyOperational 1243;
BA_ "SigType" SG_ 2565865739 ABSFullyOperational 4;
BA_ "SPN" SG_ 2565865739 EBSBrakeSwitch 1121;
BA_ "SigType" SG_ 2565865739 EBSBrakeSwitch 4;
BA_ "GenMsgCycleTime" BO_ 2566844763 100;
BA_ "GenMsgSendType" BO_ 2566844763 0;
BA_ "GenMsgStartDelayTime" BO_ 2566844763 100;
BA_ "SPN" SG_ 2566844763 BrakeSwitch 597;
BA_ "SigType" SG_ 2566844763 BrakeSwitch 4;
BA_ "SPN" SG_ 2566844763 ParkingBrakeSwitch 70;
BA_ "SigType" SG_ 2566844763 ParkingBrakeSwitch 4;
BA_ "SPN" SG_ 2566844763 CruiseCtrlEnableSwitch 596;
BA_ "SPN" SG_ 2566844763 CruiseCtrlSetSwitch 599;
BA_ "SPN" SG_ 2566844763 CruiseCtrlSetSpeed 86;
BA_ "SPN" SG_ 2566844763 CruiseCtrlStatesRequest 527;
BA_ "SPN" SG_ 2566834778 FlashRedStopLamp 3039;
BA_ "SigType" SG_ 2566834778 FlashRedStopLamp 4;
BA_ "SPN" SG_ 2566834778 FlashProtectLamp 3041;
BA_ "SigType" SG_ 2566834778 FlashProtectLamp 4;
BA_ "SPN" SG_ 2566834778 FlashMalfuncIndicatorLamp 3038;
BA_ "SigType" SG_ 2566834778 FlashMalfuncIndicatorLamp 4;
BA_ "SPN" SG_ 2566834778 FlashAmberWarningLamp 3040;
BA_ "SigType" SG_ 2566834778 FlashAmberWarningLamp 4;
BA_ "SPN" SG_ 2566834778 MalfunctionIndicatorLampStatus 1213;
BA_ "SigType" SG_ 2566834778 MalfunctionIndicatorLampStatus 4;
BA_ "SPN" SG_ 2566834778 AmberWarningLampStatus 624;
BA_ "SigType" SG_ 2566834778 AmberWarningLampStatus 4;
BA_ "SPN" SG_ 2566834778 RedStopLampState 623;
BA_ "SigType" SG_ 2566834778 RedStopLampState 4;
BA_ "SPN" SG_ 2566834778 ProtectLampStatus 987;
BA_ "SigType" SG_ 2566834778 ProtectLampStatus 4;
BA_ "SigType" SG_ 2566834778 DTC5 7;
BA_ "SigType" SG_ 2566834778 DTC4 7;
BA_ "SigType" SG_ 2566834778 DTC3 7;
BA_ "SigType" SG_ 2566834778 DTC2 7;
BA_ "SigType" SG_ 2566834778 DTC1 7;
BA_ "GenMsgCycleTime" BO_ 2566846241 1000;
BA_ "GenMsgSendType" BO_ 2566846241 0;
BA_ "SPN" SG_ 2566846241 BATT_VOLTAGE_24V 158;
BA_ "SigType" SG_ 2566846241 BATT_VOLTAGE_24V 1;
BA_ "GenMsgSendType" BO_ 2566851675 0;
BA_ "GenMsgCycleTime" BO_ 2566851675 100;
BA_ "VFrameFormat" BO_ 1365 0;
BA_ "GenMsgCycleTime" BO_ 1365 1000;
BA_ "NmStationAddress" BU_ BMS 100;
BA_ "NmJ1939Function" BU_ ZF 133;
BA_ "NmStationAddress" BU_ ZF 90;
BA_ "NmJ1939Function" BU_ ABS 45;
BA_ "NmStationAddress" BU_ ABS 11;
BA_ "NmJ1939Function" BU_ VCU 20;
BA_ "NmStationAddress" BU_ VCU 91;
VAL_ 2355220689 ASROffroadSwitch 2 "Error" 1 "ASROffroadSwitchActive" 0 "ASROffroadSwitchPassive" 3 "NotAvailable" ;
VAL_ 2355220689 CoolingAfterrunRequest 1 "EnabledForCycle" 0 "DisabledForRestOfCycle" ;
VAL_ 2355220689 CeTraxSystemReady 0 "Not Ready" 1 "Ready" ;
VAL_ 2355220689 ActualDriveMode 0 "Stop" 1 "Driving" 2 "Regen" 3 "Error" ;
VAL_ 2355220689 ActualDrivingDirection 0 "Neutral" 1 "Forward" 2 "Reverse" ;
VAL_ 2348876635 Disengage_Driveline_Request 3 "TakeNoAction" 2 "Reserved" 1 "DisengageDiffLock" 0 "EngageDiffLock" ;
VAL_ 2365545051 ElectricalSystemReady 3 "NotAvailable" 2 "Reserved" 1 "ASRBrakeCtrlActive" 0 "ASRBrakeCtrlPassiveButInstalled" ;
VAL_ 2365545051 EVSystemRelease 0 "Init" 1 "Valid driver system activation" 2 "Error" 3 "Not available" ;
VAL_ 2364539739 MessageChecksum 15 "Not Available" ;
VAL_ 2364539739 MessageCounter 14 "Reserved" 13 "Reserved" 12 "Reserved" 11 "Reserved" 10 "Reserved" 9 "Reserved" 8 "Reserved" 15 "Not Available" ;
VAL_ 2364539739 AcceleratorPedal1LowIdleSwitch 1 "Active" 2 "Inactive" ;
VAL_ 2349137450 XBRCtrlMode 3 "NotDefined" 2 "AccelerationControlWithMaxMode" 1 "AccelerationControlWithAddMode" 0 "OverrideDisabled" ;
VAL_ 2349137450 XBRPriority 3 "LwPrrtyUsdInOvrrdDsbldXBRCtrlMd" 2 "MdmPrrtyUsdFrACCSystmsThsMdDsNt" 1 "HighPriorityNotDefined" 0 "HghstPrrtyUsdFrEmrgncySttnsEgFr" ;
VAL_ 2349137450 XBREBIMode 3 "NotDefined" 2 "EndranceBrakeIntegrationAllowed" 1 "OnlyEnduranceBrakesAllowed" 0 "NEndrnceBrakeIntegrationAllowed" ;
VAL_ 2348876549 Requested_Gear 2 "Reserved" 3 "TakeNoAction" 1 "DisengageDriveline" 0 "AllowDrivelineEngagement" ;
VAL_ 2348876549 Driving_Direction 3 "TakeNoAction" 2 "Reserved" 1 "DisableTorqueConverterLockup" 0 "AllowTorqueConverterLockup" ;
VAL_ 2566840580 RetarderLocation 15 "NotAvailable" 14 "Other" 6 "1101NotDefined" 5 "Trailer" 4 "Driveline" 3 "TransOutput" 2 "TransInput" 1 "EngExhaustBrake" 0 "EngCompressionReleaseBrake" ;
VAL_ 2566840580 RetarderType 15 "NotAvailable" 14 "Other" 5 "1101NotDefined" 4 "Exhaust" 3 "CompressionRelease" 2 "CooledFriction" 1 "Hyd" 0 "Electric_Magnetic" ;
VAL_ 2566801923 TransReadyForBrakeRelease 3 "NotAvailable" 2 "Error" 1 "TransReadyForBrakeRelease" 0 "TransNotReadyForBrakeRelease" ;
VAL_ 2565866755 TransCurrentGear 251 "Park" ;
VAL_ 2565866755 TransSelectedGear 251 "Park" ;
VAL_ 2364539395 TransShiftInProcess 3 "NotAvailable" 2 "Error" 1 "ShiftInProcess" 0 "ShiftIsNotInProcess" ;
VAL_ 2364539395 TransDrivelineEngaged 3 "NotAvailable" 2 "Error" 1 "DrivelineEngaged" 0 "DrivelineDisengaged" ;
VAL_ 2565865488 RetarderEnableBrakeAssistSwitch 3 "NotAvailable" 2 "Error" 1 "RetarderBrakeAssistEnabled" 0 "RetarderBrakeAssistDisabled" ;
VAL_ 2566767627 XBRActiveCtrlMode 15 "NotAvailable" 4 "1110ReservedForSAEAssignment" 3 "MxMdOfXBRAcclrtnCtrlBngExecuted" 2 "AddtnMdOfXBRAcclrtnCtrlBngExctd" 1 "DrvrsBrkDmndBngExctdNExtlBrkDmn" 0 "NoBrakeDemandBeingExecuted" ;
VAL_ 2566767627 FoundationBrakeUse 3 "NotAvailable" 2 "Reserved" 1 "FoundationBrakesInUse" 0 "FoundationBrakesNotInUse" ;
VAL_ 2566767627 HillHolderMode 7 "NotAvailable" 6 "HillHolderNotFunctional" 3 "101Reserved" 2 "ActvBtWllChngTInctvInAShortTime" 1 "Active" 0 "Inactive" ;
VAL_ 2566767627 HaltBrakeMode 7 "NotAvailable" 6 "Reserved" 3 "101NotDefined" 2 "ActiveButNotFunctioningProperly" 1 "Active" 0 "Inactive" ;
VAL_ 2565865739 ElectricalSystemReady 3 "NotAvailable" 2 "Reserved" 1 "ASRBrakeCtrlActive" 0 "ASRBrakeCtrlPassiveButInstalled" ;
VAL_ 2565865739 HaltBrakeSwitch 3 "NotAvailable" 2 "Error" 1 "HaltBrakeSwitchActive" 0 "HaltBrakeSwitchPassive" ;
VAL_ 2565865739 ABSFullyOperational 3 "NotAvailable" 2 "Reserved" 1 "FullyOperational" 0 "NotFullyOperational" ;
VAL_ 2565865739 EBSBrakeSwitch 3 "NotAvailable" 2 "Error" 1 "BrakePedalIsBeingPressed" 0 "BrakePedalIsNotBeingPressed" ;
VAL_ 2566844763 BrakeSwitch 3 "NotAvailable" 2 "Error" 1 "BrakePedalDepressed" 0 "BrakePedalReleased" ;
VAL_ 2566844763 ParkingBrakeSwitch 3 "NotAvailable" 2 "Error" 1 "ParkingBrakeSet" 0 "ParkingBrakeNotSet" ;
VAL_ 2566844763 CruiseCtrlEnableSwitch 0 "not active" 1 "active" 10 "error" 11 "not available" ;
VAL_ 2566844763 CruiseCtrlSetSwitch 0 "not active" 1 "active" 2 "error" 3 "not available" ;
VAL_ 2566844763 CruiseCtrlStatesRequest 1 "CruiseCtrlReq" 6 "SpeedLimiterReq" ;
VAL_ 2566834778 FlashRedStopLamp 3 "Unavailable / Do Not Flash" 2 "Reserved" 1 "Fast Flash" 0 "Slow Flash" ;
VAL_ 2566834778 FlashProtectLamp 3 "Unavailable / Do Not Flash" 2 "Reserved" 1 "Fast Flash" 0 "Slow Flash" ;
VAL_ 2566834778 FlashMalfuncIndicatorLamp 3 "Unavailable / Do Not Flash" 2 "Reserved" 1 "Fast Flash" 0 "Slow Flash" ;
VAL_ 2566834778 FlashAmberWarningLamp 3 "Unavailable / Do Not Flash" 2 "Reserved" 1 "Fast Flash" 0 "Slow Flash" ;
VAL_ 2566834778 MalfunctionIndicatorLampStatus 3 "Not available" 2 "Reserved" 1 "Lamp on" 0 "Lamp off" ;
VAL_ 2566834778 AmberWarningLampStatus 3 "Not available" 2 "Reserved" 1 "Lamp on" 0 "Lamp off" ;
VAL_ 2566834778 RedStopLampState 3 "Not available" 2 "Reserved" 1 "Lamp on" 0 "Lamp off" ;
VAL_ 2566834778 ProtectLampStatus 3 "Not available" 2 "Reserved" 1 "Lamp on" 0 "Lamp off" ;
VAL_ 2566844762 SpeedLimiterFunctionActive 0 "Not active" 1 "Active" 2 "Error" 3 "Not Available" ;
VAL_ 2566844762 CruiseControlFunctionActive 0 "Not active" 1 "active" 2 "error" 3 "not available" ;
